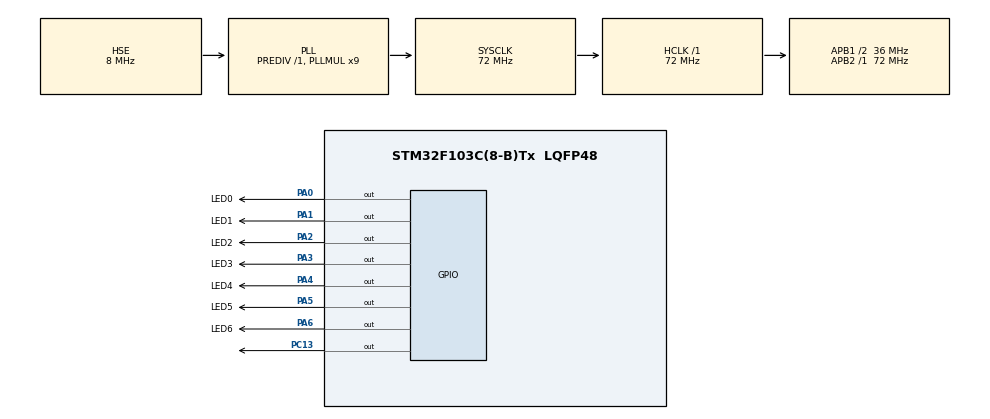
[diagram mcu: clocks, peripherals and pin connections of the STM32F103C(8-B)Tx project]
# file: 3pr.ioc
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Mcu.Family=STM32F1
Mcu.Name=STM32F103C(8-B)Tx
Mcu.Package=LQFP48
NVIC.PriorityGroup=NVIC_PRIORITYGROUP_4
NVIC.TIM2_IRQn=true\:0\:0\:false\:false\:true\:true\:true\:true
PA0-WKUP.GPIO_Label=LED0
PA0-WKUP.GPIO_PuPd=GPIO_PULLDOWN
PA0-WKUP.GPIO_Speed=GPIO_SPEED_FREQ_HIGH
PA0-WKUP.Signal=GPIO_Output
PA1.GPIO_Label=LED1
PA1.GPIO_PuPd=GPIO_PULLDOWN
PA1.GPIO_Speed=GPIO_SPEED_FREQ_HIGH
PA1.Signal=GPIO_Output
PA13.Mode=Serial_Wire
PA13.Signal=SYS_JTMS-SWDIO
PA14.Mode=Serial_Wire
PA14.Signal=SYS_JTCK-SWCLK
PA2.GPIO_Label=LED2
PA2.GPIO_PuPd=GPIO_PULLDOWN
PA2.GPIO_Speed=GPIO_SPEED_FREQ_HIGH
PA2.Signal=GPIO_Output
PA3.GPIO_Label=LED3
PA3.GPIO_PuPd=GPIO_PULLUP
PA3.GPIO_Speed=GPIO_SPEED_FREQ_HIGH
PA3.Signal=GPIO_Output
PA4.GPIO_Label=LED4
PA4.GPIO_PuPd=GPIO_PULLUP
PA4.GPIO_Speed=GPIO_SPEED_FREQ_HIGH
PA4.Signal=GPIO_Output
PA5.GPIO_Label=LED5
PA5.GPIO_PuPd=GPIO_PULLUP
PA5.GPIO_Speed=GPIO_SPEED_FREQ_HIGH
PA5.Signal=GPIO_Output
PA6.GPIO_Label=LED6
PA6.GPIO_PuPd=GPIO_PULLUP
PA6.GPIO_Speed=GPIO_SPEED_FREQ_HIGH
PA6.Signal=GPIO_Output
PC13-TAMPER-RTC.GPIO_PuPd=GPIO_NOPULL
PC13-TAMPER-RTC.GPIO_Speed=GPIO_SPEED_FREQ_HIGH
PC13-TAMPER-RTC.Signal=GPIO_Output
PD0-OSC_IN.Mode=HSE-External-Oscillator
PD0-OSC_IN.Signal=RCC_OSC_IN
PD1-OSC_OUT.Mode=HSE-External-Oscillator
PD1-OSC_OUT.Signal=RCC_OSC_OUT
ProjectManager.HeapSize=0x200
ProjectManager.StackSize=0x400
ProjectManager.TargetToolchain=STM32CubeIDE
RCC.AHBFreq_Value=72000000
RCC.APB1CLKDivider=RCC_HCLK_DIV2
RCC.APB1Freq_Value=36000000
RCC.APB1TimFreq_Value=72000000
RCC.APB2Freq_Value=72000000
RCC.APB2TimFreq_Value=72000000
RCC.HCLKFreq_Value=72000000
RCC.PLLMUL=RCC_PLL_MUL9
RCC.PLLSourceVirtual=RCC_PLLSOURCE_HSE
RCC.SYSCLKFreq_VALUE=72000000
RCC.SYSCLKSource=RCC_SYSCLKSOURCE_PLLCLK
RCC.USBFreq_Value=72000000
TIM2.Period=9999
TIM2.Prescaler=7199
VP_TIM2_VS_ClockSourceINT.Mode=Internal
board=custom

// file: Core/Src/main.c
/* USER CODE BEGIN Header */
/**
  ******************************************************************************
  * @file           : main.c
  * @brief          : Main program body
  ******************************************************************************
  * @attention
  *
  * Copyright (c) 2024 STMicroelectronics.
  * All rights reserved.
  *
  * This software is licensed under terms that can be found in the LICENSE file
  * in the root directory of this software component.
  * If no LICENSE file comes with this software, it is provided AS-IS.
  *
  ******************************************************************************
  */
/* USER CODE END Header */
#include "main.h"

TIM_HandleTypeDef htim2;

/* USER CODE BEGIN PV */
//!
volatile uint8_t countSecond = 0;
/* USER CODE END PV */

void SystemClock_Config(void);
static void MX_GPIO_Init(void);
static void MX_TIM2_Init(void);
/* USER CODE BEGIN PFP */
//!
void displaySecond(void);
/* USER CODE END PFP */

int main(void)
{

  /* MCU Configuration--------------------------------------------------------*/

  /* Reset of all peripherals, Initializes the Flash interface and the Systick. */
  HAL_Init();

  /* Configure the system clock */
  SystemClock_Config();

  /* Initialize all configured peripherals */
  MX_GPIO_Init();
  MX_TIM2_Init();
  /* USER CODE BEGIN 2 */
  //!
  HAL_TIM_Base_Start_IT(&htim2);
  /* USER CODE END 2 */

  /* Infinite loop */
  while (1)
  {

  }
}

void SystemClock_Config(void)
{
  RCC_OscInitTypeDef RCC_OscInitStruct = {0};
  RCC_ClkInitTypeDef RCC_ClkInitStruct = {0};

  /** Initializes the RCC Oscillators according to the specified parameters
  * in the RCC_OscInitTypeDef structure.
  */
  RCC_OscInitStruct.OscillatorType = RCC_OSCILLATORTYPE_HSE;
  RCC_OscInitStruct.HSEState = RCC_HSE_ON;
  RCC_OscInitStruct.HSEPredivValue = RCC_HSE_PREDIV_DIV1;
  RCC_OscInitStruct.HSIState = RCC_HSI_ON;
  RCC_OscInitStruct.PLL.PLLState = RCC_PLL_ON;
  RCC_OscInitStruct.PLL.PLLSource = RCC_PLLSOURCE_HSE;
  RCC_OscInitStruct.PLL.PLLMUL = RCC_PLL_MUL9;
  if (HAL_RCC_OscConfig(&RCC_OscInitStruct) != HAL_OK)
  {
    Error_Handler();
  }

  /** Initializes the CPU, AHB and APB buses clocks
  */
  RCC_ClkInitStruct.ClockType = RCC_CLOCKTYPE_HCLK|RCC_CLOCKTYPE_SYSCLK
                              |RCC_CLOCKTYPE_PCLK1|RCC_CLOCKTYPE_PCLK2;
  RCC_ClkInitStruct.SYSCLKSource = RCC_SYSCLKSOURCE_PLLCLK;
  RCC_ClkInitStruct.AHBCLKDivider = RCC_SYSCLK_DIV1;
  RCC_ClkInitStruct.APB1CLKDivider = RCC_HCLK_DIV2;
  RCC_ClkInitStruct.APB2CLKDivider = RCC_HCLK_DIV1;

  if (HAL_RCC_ClockConfig(&RCC_ClkInitStruct, FLASH_LATENCY_2) != HAL_OK)
  {
    Error_Handler();
  }
}

static void MX_TIM2_Init(void)
{

  TIM_ClockConfigTypeDef sClockSourceConfig = {0};
  TIM_MasterConfigTypeDef sMasterConfig = {0};

  htim2.Instance = TIM2;
  htim2.Init.Prescaler = 7199;
  htim2.Init.CounterMode = TIM_COUNTERMODE_UP;
  htim2.Init.Period = 9999;
  htim2.Init.ClockDivision = TIM_CLOCKDIVISION_DIV1;
  htim2.Init.AutoReloadPreload = TIM_AUTORELOAD_PRELOAD_DISABLE;
  if (HAL_TIM_Base_Init(&htim2) != HAL_OK)
  {
    Error_Handler();
  }
  sClockSourceConfig.ClockSource = TIM_CLOCKSOURCE_INTERNAL;
  if (HAL_TIM_ConfigClockSource(&htim2, &sClockSourceConfig) != HAL_OK)
  {
    Error_Handler();
  }
  sMasterConfig.MasterOutputTrigger = TIM_TRGO_RESET;
  sMasterConfig.MasterSlaveMode = TIM_MASTERSLAVEMODE_DISABLE;
  if (HAL_TIMEx_MasterConfigSynchronization(&htim2, &sMasterConfig) != HAL_OK)
  {
    Error_Handler();
  }

}

static void MX_GPIO_Init(void)
{
  GPIO_InitTypeDef GPIO_InitStruct = {0};

  /* GPIO Ports Clock Enable */
  __HAL_RCC_GPIOC_CLK_ENABLE();
  __HAL_RCC_GPIOD_CLK_ENABLE();
  __HAL_RCC_GPIOA_CLK_ENABLE();

  /*Configure GPIO pin Output Level */
  HAL_GPIO_WritePin(GPIOC, GPIO_PIN_13, GPIO_PIN_RESET);

  /*Configure GPIO pin Output Level */
  HAL_GPIO_WritePin(GPIOA, LED0_Pin|LED1_Pin|LED2_Pin|LED3_Pin
                          |LED4_Pin|LED5_Pin|LED6_Pin, GPIO_PIN_RESET);

  /*Configure GPIO pin : PC13 */
  GPIO_InitStruct.Pin = GPIO_PIN_13;
  GPIO_InitStruct.Mode = GPIO_MODE_OUTPUT_PP;
  GPIO_InitStruct.Pull = GPIO_NOPULL;
  GPIO_InitStruct.Speed = GPIO_SPEED_FREQ_HIGH;
  HAL_GPIO_Init(GPIOC, &GPIO_InitStruct);

  /*Configure GPIO pins : LED0_Pin LED1_Pin LED2_Pin */
  GPIO_InitStruct.Pin = LED0_Pin|LED1_Pin|LED2_Pin;
  GPIO_InitStruct.Mode = GPIO_MODE_OUTPUT_PP;
  GPIO_InitStruct.Pull = GPIO_PULLDOWN;
  GPIO_InitStruct.Speed = GPIO_SPEED_FREQ_HIGH;
  HAL_GPIO_Init(GPIOA, &GPIO_InitStruct);

  /*Configure GPIO pins : LED3_Pin LED4_Pin LED5_Pin LED6_Pin */
  GPIO_InitStruct.Pin = LED3_Pin|LED4_Pin|LED5_Pin|LED6_Pin;
  GPIO_InitStruct.Mode = GPIO_MODE_OUTPUT_PP;
  GPIO_InitStruct.Pull = GPIO_PULLUP;
  GPIO_InitStruct.Speed = GPIO_SPEED_FREQ_HIGH;
  HAL_GPIO_Init(GPIOA, &GPIO_InitStruct);

}

/* USER CODE BEGIN 4 */
//!
void displaySecond(void){
 HAL_GPIO_WritePin(GPIOA, LED0_Pin,
   ((countSecond & 1) >> 0 ? GPIO_PIN_SET: GPIO_PIN_RESET));
 HAL_GPIO_WritePin(GPIOA, LED1_Pin,
   ((countSecond & 2) >> 1 ? GPIO_PIN_SET: GPIO_PIN_RESET));
 HAL_GPIO_WritePin(GPIOA, LED2_Pin,
   ((countSecond & 7) >> 2 ? GPIO_PIN_SET: GPIO_PIN_RESET));
 countSecond ++;
 if (countSecond == 8);
 HAL_GPIO_TogglePin (GPIOC, GPIO_PIN_13);
}
/* USER CODE END 4 */

void Error_Handler(void)
{
  __disable_irq();
  while (1)
  {
  }
}
